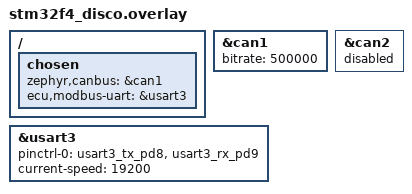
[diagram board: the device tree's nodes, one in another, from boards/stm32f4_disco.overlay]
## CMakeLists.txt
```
# SPDX-License-Identifier: Apache-2.0

cmake_minimum_required(VERSION 3.20.0)

find_package(Zephyr REQUIRED HINTS $ENV{ZEPHYR_BASE})
project(sensor_ecu LANGUAGES C)

target_include_directories(app PRIVATE src)

target_sources(app PRIVATE
  src/main.c
  src/data_model.c
  src/sensors_sim.c
  src/crc.c
  src/can_codec.c
  src/can_app.c
  src/dtc.c
  src/uds.c
  src/uds_server.c
  src/modbus_map.c
  src/modbus_rtu.c
  src/modbus_server.c
)
```

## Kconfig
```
# SPDX-License-Identifier: Apache-2.0

mainmenu "Sensor ECU"

config ECU_MODBUS_MIN_FRAME_GAP_US
	int "Minimum Modbus RTU silent interval (us)"
	default 0
	help
	  Lower bound for the RTU end-of-frame silent interval. On real UARTs
	  t3.5 is computed from the baud rate. A pseudo terminal delivers
	  bytes in bursts with host scheduling jitter, so the native_sim
	  build raises the bound to avoid splitting frames.

source "Kconfig.zephyr"
```

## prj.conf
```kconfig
# Logging
CONFIG_LOG=y
CONFIG_LOG_MODE_DEFERRED=y

# CAN + ISO-TP
CONFIG_CAN=y
CONFIG_ISOTP=y
CONFIG_ISOTP_RX_BUF_COUNT=4
CONFIG_ISOTP_RX_SF_FF_BUF_COUNT=2

# Modbus server fed through the raw ADU interface (see modbus_rtu.h)
CONFIG_MODBUS=y
CONFIG_MODBUS_ROLE_SERVER=y
CONFIG_MODBUS_RAW_ADU=y
CONFIG_MODBUS_NUMOF_RAW_ADU=1

# UART interrupt API for the RTU framer
CONFIG_SERIAL=y
CONFIG_UART_INTERRUPT_DRIVEN=y
CONFIG_UART_USE_RUNTIME_CONFIGURE=y

CONFIG_MAIN_STACK_SIZE=2048
CONFIG_SYSTEM_WORKQUEUE_STACK_SIZE=2048
CONFIG_THREAD_NAME=y
```

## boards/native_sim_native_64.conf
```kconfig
# A PTY delivers bytes with host scheduling jitter; see Kconfig help.
CONFIG_ECU_MODBUS_MIN_FRAME_GAP_US=5000
```

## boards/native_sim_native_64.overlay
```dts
/*
 * native_sim: CAN goes to the host SocketCAN interface vcan0 (override at
 * run time with --can-if), Modbus RTU runs on a second pseudo terminal.
 *
 * SPDX-License-Identifier: Apache-2.0
 */

/ {
	chosen {
		zephyr,canbus = &can0;
		ecu,modbus-uart = &uart1;
	};
};

&can0 {
	status = "okay";
	host-interface = "vcan0";
};

&uart1 {
	status = "okay";
};
```

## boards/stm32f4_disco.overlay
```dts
/*
 * STM32F4 Discovery (also what Renode emulates): CAN1 (PD0/PD1) at
 * 500 kbit/s, Modbus RTU on USART3 (PD8/PD9), console stays on USART2.
 *
 * CAN1 rather than the board default CAN2: CAN1 owns the shared filter
 * banks, and for the CAN2 slave Renode's STMCAN model numbers the filter
 * match index across all 28 banks instead of from CAN2SB as silicon does,
 * so Zephyr would route every received frame to no callback.
 *
 * SPDX-License-Identifier: Apache-2.0
 */

/ {
	chosen {
		zephyr,canbus = &can1;
		ecu,modbus-uart = &usart3;
	};
};

&can1 {
	bitrate = <500000>;
};

&can2 {
	status = "disabled";
};

&usart3 {
	pinctrl-0 = <&usart3_tx_pd8 &usart3_rx_pd9>;
	pinctrl-names = "default";
	current-speed = <19200>;
	status = "okay";
};
```

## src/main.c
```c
/*
 * Virtual industrial and automotive sensor node.
 *
 * main() owns the sampling loop and the slow supervision checks; CAN, UDS
 * and Modbus run in their own threads and only meet in the data model.
 *
 * SPDX-License-Identifier: Apache-2.0
 */

#include <zephyr/kernel.h>
#include <zephyr/logging/log.h>

#include "data_model.h"
#include "dtc.h"
#include "ecu_config.h"
#include "ecu_tasks.h"
#include "modbus_map.h"
#include "sensors_sim.h"

LOG_MODULE_REGISTER(main, LOG_LEVEL_INF);

int main(void)
{
	LOG_INF("Sensor ECU %s starting (serial %s)", ECU_FW_VERSION, ECU_SERIAL_NUMBER);

	dm_init();
	dtc_init();
	sensors_sim_init(0xC0FFEE);

	bool can_ok = can_app_start() == 0;

	if (can_ok && uds_server_start() != 0) {
		LOG_ERR("UDS server failed to start");
	}
	if (modbus_server_start() != 0) {
		LOG_ERR("Modbus server failed to start");
	}

	dm_set_state(FW_STATE_RUN);
	LOG_INF("ECU running (CAN %s)", can_ok ? "up" : "DOWN");

	bool sensor_fault_logged = false;

	while (true) {
		struct dm_snapshot s;
		struct sensor_sample sample;

		dm_get(&s);
		sensors_sim_sample(k_uptime_get_32(), s.fault_injection, &sample);
		dm_update_sensors(sample.temperature_dC, sample.vibration_cmm_s,
				  sample.out_of_range);

		dtc_report(DTC_SENSOR_OUT_OF_RANGE, sample.out_of_range);
		dtc_report(DTC_MODBUS_MASTER_TIMEOUT, mb_link_timed_out(k_uptime_get()));

		if (sample.out_of_range != sensor_fault_logged) {
			sensor_fault_logged = sample.out_of_range;
			LOG_INF("Sensor %s", sensor_fault_logged ? "out of range" : "back in range");
		}

		k_sleep(K_MSEC(s.sample_period_ms));
	}

	return 0;
}
```

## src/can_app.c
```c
/*
 * CAN front end: periodic SENSOR_STATUS / HEARTBEAT transmission and
 * ECU_COMMAND reception with rolling counter and CRC checks.
 *
 * SPDX-License-Identifier: Apache-2.0
 */

#include <string.h>

#include <zephyr/device.h>
#include <zephyr/devicetree.h>
#include <zephyr/drivers/can.h>
#include <zephyr/kernel.h>
#include <zephyr/logging/log.h>

#include "can_codec.h"
#include "data_model.h"
#include "dtc.h"
#include "ecu_config.h"
#include "ecu_tasks.h"

LOG_MODULE_REGISTER(can_app, LOG_LEVEL_INF);

#define CAN_TX_STACK 1024
#define CAN_RX_STACK 1024
#define CAN_TX_PRIO  5
#define CAN_RX_PRIO  6

static const struct device *const can_dev = DEVICE_DT_GET(DT_CHOSEN(zephyr_canbus));

CAN_MSGQ_DEFINE(cmd_msgq, 8);

K_THREAD_STACK_DEFINE(can_tx_stack, CAN_TX_STACK);
K_THREAD_STACK_DEFINE(can_rx_stack, CAN_RX_STACK);
static struct k_thread can_tx_thread;
static struct k_thread can_rx_thread;

static int send_frame(uint32_t id, const uint8_t data[8])
{
	struct can_frame frame = {
		.id = id,
		.dlc = CAN_CODEC_DLC,
	};

	memcpy(frame.data, data, CAN_CODEC_DLC);
	return can_send(can_dev, &frame, K_MSEC(20), NULL, NULL);
}

static void can_tx_loop(void *p1, void *p2, void *p3)
{
	int64_t next = k_uptime_get();
	uint8_t counter = 0;
	uint32_t ticks = 0;

	while (true) {
		struct dm_snapshot s;
		uint8_t data[8];

		dm_get(&s);

		struct sensor_status_msg status = {
			.temperature_dC = s.temperature_dC,
			.vibration_cmm_s = s.vibration_cmm_s,
			.alarm_active = s.alarm_active,
			.sensor_fault = s.sensor_fault,
			.counter = counter,
		};

		can_codec_pack_sensor_status(&status, data);
		if (send_frame(CAN_ID_SENSOR_STATUS, data) != 0) {
			LOG_DBG("SENSOR_STATUS not sent");
		}
		counter = (counter + 1) & 0x0F;

		if (ticks % (HEARTBEAT_PERIOD_MS / SENSOR_STATUS_PERIOD_MS) == 0) {
			size_t active = dtc_count_by_mask(DTC_STATUS_TEST_FAILED);
			struct heartbeat_msg hb = {
				.uptime_s = s.uptime_s,
				.fw_state = active ? FW_STATE_DEGRADED : s.state,
				.active_dtcs = (uint8_t)active,
			};

			can_codec_pack_heartbeat(&hb, data);
			(void)send_frame(CAN_ID_HEARTBEAT, data);
		}
		ticks++;

		/* Absolute deadlines keep the period free of cumulative drift. */
		next += SENSOR_STATUS_PERIOD_MS;
		k_sleep(K_TIMEOUT_ABS_MS(next));
	}
}

static void apply_command(const struct ecu_command_msg *cmd)
{
	if (cmd->sample_period_ms != CMD_SAMPLE_PERIOD_KEEP &&
	    dm_set_sample_period(cmd->sample_period_ms) != 0) {
		LOG_WRN("ECU_COMMAND: sample period %u out of range", cmd->sample_period_ms);
	}
	if (cmd->alarm_threshold_dC != CMD_ALARM_THRESHOLD_KEEP &&
	    dm_set_alarm_threshold(cmd->alarm_threshold_dC) != 0) {
		LOG_WRN("ECU_COMMAND: threshold %d out of range", cmd->alarm_threshold_dC);
	}
	dm_set_fault_injection(cmd->fault_injection);
	if (cmd->alarm_reset) {
		dm_reset_alarm();
	}

	LOG_INF("ECU_COMMAND applied: period=%u threshold=%d fault=%d reset=%d",
		cmd->sample_period_ms, cmd->alarm_threshold_dC, cmd->fault_injection,
		cmd->alarm_reset);
}

static void can_rx_loop(void *p1, void *p2, void *p3)
{
	struct can_frame frame;
	int last_counter = -1;

	while (true) {
		struct ecu_command_msg cmd;

		k_msgq_get(&cmd_msgq, &frame, K_FOREVER);

		int err = can_codec_unpack_ecu_command(frame.data, frame.dlc, &cmd);

		if (err == -EBADMSG) {
			LOG_WRN("ECU_COMMAND rejected: CRC error");
			dtc_report(DTC_COMMAND_CRC_ERROR, true);
			continue;
		}
		if (err) {
			LOG_WRN("ECU_COMMAND rejected: DLC %u", frame.dlc);
			continue;
		}
		dtc_report(DTC_COMMAND_CRC_ERROR, false);

		/* A repeated counter means a stale or replayed frame. */
		if (cmd.counter == last_counter) {
			LOG_WRN("ECU_COMMAND rejected: repeated counter %u", cmd.counter);
			continue;
		}
		last_counter = cmd.counter;

		apply_command(&cmd);
	}
}

static void can_state_changed(const struct device *dev, enum can_state state,
			      struct can_bus_err_cnt err_cnt, void *user_data)
{
	static bool was_bus_off;

	if (state == CAN_STATE_BUS_OFF) {
		was_bus_off = true;
		dtc_report(DTC_CAN_BUS_OFF, true);
	} else if (was_bus_off && state == CAN_STATE_ERROR_ACTIVE) {
		/* Recovered: testFailed clears, confirmed stays for the tester. */
		was_bus_off = false;
		dtc_report(DTC_CAN_BUS_OFF, false);
	}
}

const struct device *can_app_device(void)
{
	return can_dev;
}

int can_app_start(void)
{
	const struct can_filter cmd_filter = {
		.id = CAN_ID_ECU_COMMAND,
		.mask = CAN_STD_ID_MASK,
		.flags = 0,
	};
	int err;

	if (!device_is_ready(can_dev)) {
		LOG_ERR("CAN device %s not ready", can_dev->name);
		return -ENODEV;
	}

	err = can_set_bitrate(can_dev, CAN_BITRATE);
	if (err && err != -ENOTSUP && err != -ENOSYS) {
		LOG_WRN("can_set_bitrate: %d", err);
	}

	can_set_state_change_callback(can_dev, can_state_changed, NULL);

	err = can_add_rx_filter_msgq(can_dev, &cmd_msgq, &cmd_filter);
	if (err < 0) {
		LOG_ERR("ECU_COMMAND filter: %d", err);
		return err;
	}

	err = can_start(can_dev);
	if (err && err != -EALREADY) {
		LOG_ERR("can_start: %d", err);
		return err;
	}

	k_thread_create(&can_tx_thread, can_tx_stack, K_THREAD_STACK_SIZEOF(can_tx_stack),
			can_tx_loop, NULL, NULL, NULL, CAN_TX_PRIO, 0, K_NO_WAIT);
	k_thread_name_set(&can_tx_thread, "can_tx");
	k_thread_create(&can_rx_thread, can_rx_stack, K_THREAD_STACK_SIZEOF(can_rx_stack),
			can_rx_loop, NULL, NULL, NULL, CAN_RX_PRIO, 0, K_NO_WAIT);
	k_thread_name_set(&can_rx_thread, "can_rx");

	LOG_INF("CAN up on %s, %u bit/s", can_dev->name, CAN_BITRATE);
	return 0;
}
```

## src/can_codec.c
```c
/*
 * SPDX-License-Identifier: Apache-2.0
 */

#include <errno.h>
#include <string.h>

#include "can_codec.h"
#include "crc.h"

#define CRC_BYTE     7
#define COUNTER_BYTE 6

static void put_le16(uint8_t *p, uint16_t v)
{
	p[0] = (uint8_t)v;
	p[1] = (uint8_t)(v >> 8);
}

static uint16_t get_le16(const uint8_t *p)
{
	return (uint16_t)(p[0] | (p[1] << 8));
}

static void seal(uint8_t data[8], uint8_t counter)
{
	data[COUNTER_BYTE] = counter & 0x0F;
	data[CRC_BYTE] = crc8_sae_j1850(data, CRC_BYTE);
}

static int check(const uint8_t *data, uint8_t dlc)
{
	if (dlc != CAN_CODEC_DLC) {
		return -EINVAL;
	}
	if (crc8_sae_j1850(data, CRC_BYTE) != data[CRC_BYTE]) {
		return -EBADMSG;
	}
	return 0;
}

void can_codec_pack_sensor_status(const struct sensor_status_msg *msg, uint8_t data[8])
{
	memset(data, 0, CAN_CODEC_DLC);
	put_le16(&data[0], (uint16_t)msg->temperature_dC);
	put_le16(&data[2], msg->vibration_cmm_s);
	data[4] = (msg->alarm_active ? 0x01 : 0) | (msg->sensor_fault ? 0x02 : 0);
	seal(data, msg->counter);
}

int can_codec_unpack_sensor_status(const uint8_t *data, uint8_t dlc, struct sensor_status_msg *msg)
{
	int err = check(data, dlc);

	if (err) {
		return err;
	}
	msg->temperature_dC = (int16_t)get_le16(&data[0]);
	msg->vibration_cmm_s = get_le16(&data[2]);
	msg->alarm_active = data[4] & 0x01;
	msg->sensor_fault = data[4] & 0x02;
	msg->counter = data[COUNTER_BYTE] & 0x0F;
	return 0;
}

/* HEARTBEAT is not safety relevant, so it carries no counter or CRC. */
void can_codec_pack_heartbeat(const struct heartbeat_msg *msg, uint8_t data[8])
{
	memset(data, 0, CAN_CODEC_DLC);
	put_le16(&data[0], (uint16_t)msg->uptime_s);
	put_le16(&data[2], (uint16_t)(msg->uptime_s >> 16));
	data[4] = msg->fw_state;
	data[5] = msg->active_dtcs;
}

int can_codec_unpack_heartbeat(const uint8_t *data, uint8_t dlc, struct heartbeat_msg *msg)
{
	if (dlc != CAN_CODEC_DLC) {
		return -EINVAL;
	}
	msg->uptime_s = get_le16(&data[0]) | ((uint32_t)get_le16(&data[2]) << 16);
	msg->fw_state = data[4];
	msg->active_dtcs = data[5];
	return 0;
}

void can_codec_pack_ecu_command(const struct ecu_command_msg *msg, uint8_t data[8])
{
	memset(data, 0, CAN_CODEC_DLC);
	put_le16(&data[0], msg->sample_period_ms);
	put_le16(&data[2], (uint16_t)msg->alarm_threshold_dC);
	data[4] = (msg->fault_injection ? 0x01 : 0) | (msg->alarm_reset ? 0x02 : 0);
	seal(data, msg->counter);
}

int can_codec_unpack_ecu_command(const uint8_t *data, uint8_t dlc, struct ecu_command_msg *msg)
{
	int err = check(data, dlc);

	if (err) {
		return err;
	}
	msg->sample_period_ms = get_le16(&data[0]);
	msg->alarm_threshold_dC = (int16_t)get_le16(&data[2]);
	msg->fault_injection = data[4] & 0x01;
	msg->alarm_reset = data[4] & 0x02;
	msg->counter = data[COUNTER_BYTE] & 0x0F;
	return 0;
}
```

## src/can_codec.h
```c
/*
 * Pack and unpack the project CAN messages. The bit layout here must match
 * dbc/sensor_ecu.dbc; the integration tests decode live frames with cantools
 * to prove that it does.
 *
 * All multi-byte signals are little endian (Intel). Byte 6 carries a 4-bit
 * rolling counter and byte 7 a CRC-8 SAE J1850 over bytes 0..6.
 *
 * SPDX-License-Identifier: Apache-2.0
 */

#ifndef CAN_CODEC_H_
#define CAN_CODEC_H_

#include <stdbool.h>
#include <stdint.h>

#define CAN_CODEC_DLC 8

struct sensor_status_msg {
	int16_t temperature_dC;   /* 0.1 degC */
	uint16_t vibration_cmm_s; /* 0.01 mm/s */
	bool alarm_active;
	bool sensor_fault;
	uint8_t counter;          /* 0..15 */
};

struct heartbeat_msg {
	uint32_t uptime_s;
	uint8_t fw_state;
	uint8_t active_dtcs;
};

struct ecu_command_msg {
	uint16_t sample_period_ms; /* CMD_SAMPLE_PERIOD_KEEP = no change */
	int16_t alarm_threshold_dC; /* CMD_ALARM_THRESHOLD_KEEP = no change */
	bool fault_injection;
	bool alarm_reset;
	uint8_t counter;          /* 0..15 */
};

void can_codec_pack_sensor_status(const struct sensor_status_msg *msg, uint8_t data[8]);
int can_codec_unpack_sensor_status(const uint8_t *data, uint8_t dlc,
				   struct sensor_status_msg *msg);

void can_codec_pack_heartbeat(const struct heartbeat_msg *msg, uint8_t data[8]);
int can_codec_unpack_heartbeat(const uint8_t *data, uint8_t dlc, struct heartbeat_msg *msg);

void can_codec_pack_ecu_command(const struct ecu_command_msg *msg, uint8_t data[8]);
/* Returns 0, -EINVAL for a wrong DLC or -EBADMSG for a CRC mismatch. */
int can_codec_unpack_ecu_command(const uint8_t *data, uint8_t dlc, struct ecu_command_msg *msg);

#endif /* CAN_CODEC_H_ */
```

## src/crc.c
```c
/*
 * SPDX-License-Identifier: Apache-2.0
 */

#include "crc.h"

uint8_t crc8_sae_j1850(const uint8_t *data, size_t len)
{
	uint8_t crc = 0xFF;

	for (size_t i = 0; i < len; i++) {
		crc ^= data[i];
		for (int bit = 0; bit < 8; bit++) {
			crc = (crc & 0x80) ? (uint8_t)((crc << 1) ^ 0x1D) : (uint8_t)(crc << 1);
		}
	}

	return crc ^ 0xFF;
}

uint16_t crc16_modbus(const uint8_t *data, size_t len)
{
	uint16_t crc = 0xFFFF;

	for (size_t i = 0; i < len; i++) {
		crc ^= data[i];
		for (int bit = 0; bit < 8; bit++) {
			crc = (crc & 1) ? (crc >> 1) ^ 0xA001 : crc >> 1;
		}
	}
	return crc;
}
```

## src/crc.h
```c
/*
 * Checksums used on the two buses.
 *
 * SPDX-License-Identifier: Apache-2.0
 */

#ifndef CRC_H_
#define CRC_H_

#include <stddef.h>
#include <stdint.h>

/* CRC-8 SAE J1850 (poly 0x1D, init 0xFF, xorout 0xFF), as in AUTOSAR E2E. */
uint8_t crc8_sae_j1850(const uint8_t *data, size_t len);

/* Modbus RTU CRC-16 (poly 0xA001 reflected, init 0xFFFF). */
uint16_t crc16_modbus(const uint8_t *data, size_t len);

#endif /* CRC_H_ */
```

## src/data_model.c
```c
/*
 * SPDX-License-Identifier: Apache-2.0
 */

#include <errno.h>

#include <zephyr/kernel.h>

#include "data_model.h"
#include "ecu_config.h"

static K_MUTEX_DEFINE(dm_lock);

static struct {
	int16_t temperature_dC;
	uint16_t vibration_cmm_s;
	bool alarm_active;
	bool sensor_fault;
	bool fault_injection;
	uint16_t sample_period_ms;
	int16_t alarm_threshold_dC;
	enum fw_state state;
} dm;

/* Caller holds dm_lock. The alarm latches: crossing the threshold sets it,
 * only dm_reset_alarm() clears it.
 */
static void evaluate_alarm(void)
{
	if (dm.temperature_dC > dm.alarm_threshold_dC) {
		dm.alarm_active = true;
	}
}

void dm_init(void)
{
	k_mutex_lock(&dm_lock, K_FOREVER);
	dm.temperature_dC = 0;
	dm.vibration_cmm_s = 0;
	dm.alarm_active = false;
	dm.sensor_fault = false;
	dm.fault_injection = false;
	dm.sample_period_ms = SAMPLE_PERIOD_DEFAULT_MS;
	dm.alarm_threshold_dC = ALARM_THRESHOLD_DEFAULT;
	dm.state = FW_STATE_INIT;
	k_mutex_unlock(&dm_lock);
}

void dm_get(struct dm_snapshot *out)
{
	k_mutex_lock(&dm_lock, K_FOREVER);
	out->temperature_dC = dm.temperature_dC;
	out->vibration_cmm_s = dm.vibration_cmm_s;
	out->alarm_active = dm.alarm_active;
	out->sensor_fault = dm.sensor_fault;
	out->fault_injection = dm.fault_injection;
	out->sample_period_ms = dm.sample_period_ms;
	out->alarm_threshold_dC = dm.alarm_threshold_dC;
	out->state = dm.state;
	k_mutex_unlock(&dm_lock);

	out->uptime_s = (uint32_t)(k_uptime_get() / 1000);
}

int dm_set_sample_period(uint16_t period_ms)
{
	if (period_ms < SAMPLE_PERIOD_MIN_MS || period_ms > SAMPLE_PERIOD_MAX_MS) {
		return -EINVAL;
	}
	k_mutex_lock(&dm_lock, K_FOREVER);
	dm.sample_period_ms = period_ms;
	k_mutex_unlock(&dm_lock);
	return 0;
}

int dm_set_alarm_threshold(int16_t threshold_dC)
{
	if (threshold_dC < ALARM_THRESHOLD_MIN || threshold_dC > ALARM_THRESHOLD_MAX) {
		return -EINVAL;
	}
	k_mutex_lock(&dm_lock, K_FOREVER);
	dm.alarm_threshold_dC = threshold_dC;
	evaluate_alarm();
	k_mutex_unlock(&dm_lock);
	return 0;
}

void dm_set_fault_injection(bool enable)
{
	k_mutex_lock(&dm_lock, K_FOREVER);
	dm.fault_injection = enable;
	k_mutex_unlock(&dm_lock);
}

void dm_set_state(enum fw_state state)
{
	k_mutex_lock(&dm_lock, K_FOREVER);
	dm.state = state;
	k_mutex_unlock(&dm_lock);
}

void dm_update_sensors(int16_t temperature_dC, uint16_t vibration_cmm_s, bool sensor_fault)
{
	k_mutex_lock(&dm_lock, K_FOREVER);
	dm.temperature_dC = temperature_dC;
	dm.vibration_cmm_s = vibration_cmm_s;
	dm.sensor_fault = sensor_fault;
	evaluate_alarm();
	k_mutex_unlock(&dm_lock);
}

void dm_reset_alarm(void)
{
	k_mutex_lock(&dm_lock, K_FOREVER);
	dm.alarm_active = false;
	evaluate_alarm();
	k_mutex_unlock(&dm_lock);
}
```

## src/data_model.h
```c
/*
 * Shared sensor state. CAN, UDS and Modbus are all front ends onto this one
 * model; every access goes through a mutex so a threshold written over
 * Modbus is seen atomically by the CAN transmitter and vice versa.
 *
 * SPDX-License-Identifier: Apache-2.0
 */

#ifndef DATA_MODEL_H_
#define DATA_MODEL_H_

#include <stdbool.h>
#include <stdint.h>

enum fw_state {
	FW_STATE_INIT = 0,
	FW_STATE_RUN = 1,
	FW_STATE_DEGRADED = 2,
};

struct dm_snapshot {
	int16_t temperature_dC;
	uint16_t vibration_cmm_s;
	bool alarm_active;
	bool sensor_fault;
	bool fault_injection;
	uint16_t sample_period_ms;
	int16_t alarm_threshold_dC;
	uint32_t uptime_s;
	enum fw_state state;
};

void dm_init(void);

/* Consistent copy of the whole model, taken under the lock. */
void dm_get(struct dm_snapshot *out);

/* Setters validate ranges and return -EINVAL without changing anything. */
int dm_set_sample_period(uint16_t period_ms);
int dm_set_alarm_threshold(int16_t threshold_dC);
void dm_set_fault_injection(bool enable);
void dm_set_state(enum fw_state state);

/* New sensor values; re-evaluates the latched alarm. */
void dm_update_sensors(int16_t temperature_dC, uint16_t vibration_cmm_s, bool sensor_fault);

/*
 * Clear the latched alarm. The alarm only clears if the temperature is back
 * at or below the threshold, otherwise it stays active.
 */
void dm_reset_alarm(void);

#endif /* DATA_MODEL_H_ */
```

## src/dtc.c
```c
/*
 * SPDX-License-Identifier: Apache-2.0
 */

#include <zephyr/kernel.h>

#include "dtc.h"

/*
 * DTC numbers follow the SAE J2012 3-byte layout (2-byte code + failure
 * type byte). The U-codes reuse real network fault numbers; P0A10 is a
 * project-defined powertrain sensor code.
 */
static const uint32_t dtc_codes[DTC_COUNT] = {
	[DTC_SENSOR_OUT_OF_RANGE] = 0x0A1011,   /* P0A10-11 temperature out of range */
	[DTC_CAN_BUS_OFF] = 0xC07388,           /* U0073-88 CAN bus off */
	[DTC_MODBUS_MASTER_TIMEOUT] = 0xC10087, /* U0100-87 Modbus master missing */
	[DTC_COMMAND_CRC_ERROR] = 0xC41481,     /* U0414-81 invalid command CRC */
};

static uint8_t dtc_state[DTC_COUNT];
static struct k_spinlock dtc_lock;

void dtc_init(void)
{
	dtc_clear_all();
}

void dtc_report(enum dtc_id id, bool failed)
{
	if (id >= DTC_COUNT) {
		return;
	}

	K_SPINLOCK(&dtc_lock) {
		if (failed) {
			dtc_state[id] |= DTC_STATUS_TEST_FAILED | DTC_STATUS_TEST_FAILED_THIS_CYCLE |
					 DTC_STATUS_PENDING | DTC_STATUS_CONFIRMED;
		} else {
			dtc_state[id] &= ~DTC_STATUS_TEST_FAILED;
		}
	}
}

void dtc_clear_all(void)
{
	K_SPINLOCK(&dtc_lock) {
		for (int i = 0; i < DTC_COUNT; i++) {
			dtc_state[i] = 0;
		}
	}
}

uint32_t dtc_code(enum dtc_id id)
{
	return id < DTC_COUNT ? dtc_codes[id] : 0;
}

uint8_t dtc_status(enum dtc_id id)
{
	uint8_t status = 0;

	if (id < DTC_COUNT) {
		K_SPINLOCK(&dtc_lock) {
			status = dtc_state[id];
		}
	}
	return status;
}

size_t dtc_count_by_mask(uint8_t mask)
{
	return dtc_get_by_mask(mask, NULL, DTC_COUNT);
}

size_t dtc_get_by_mask(uint8_t mask, struct dtc_record *out, size_t max)
{
	size_t n = 0;

	K_SPINLOCK(&dtc_lock) {
		for (int i = 0; i < DTC_COUNT && n < max; i++) {
			if ((dtc_state[i] & mask) == 0) {
				continue;
			}
			if (out != NULL) {
				out[n].code = dtc_codes[i];
				out[n].status = dtc_state[i];
			}
			n++;
		}
	}
	return n;
}
```

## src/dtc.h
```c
/*
 * Diagnostic trouble code storage with ISO 14229 status bits. RAM only;
 * moving it to NVS/ZMS is the natural next step on real hardware.
 *
 * SPDX-License-Identifier: Apache-2.0
 */

#ifndef DTC_H_
#define DTC_H_

#include <stdbool.h>
#include <stddef.h>
#include <stdint.h>

enum dtc_id {
	DTC_SENSOR_OUT_OF_RANGE,
	DTC_CAN_BUS_OFF,
	DTC_MODBUS_MASTER_TIMEOUT,
	DTC_COMMAND_CRC_ERROR,
	DTC_COUNT,
};

/* ISO 14229-1 DTC status bits used by this ECU */
#define DTC_STATUS_TEST_FAILED            0x01
#define DTC_STATUS_TEST_FAILED_THIS_CYCLE 0x02
#define DTC_STATUS_PENDING                0x04
#define DTC_STATUS_CONFIRMED              0x08
#define DTC_STATUS_AVAILABILITY_MASK      0x0F

struct dtc_record {
	uint32_t code; /* 3-byte DTC number */
	uint8_t status;
};

void dtc_init(void);

/*
 * Report the result of a monitor. failed=true sets testFailed, pending and
 * confirmed. failed=false clears testFailed only, so a recovered fault
 * stays visible as confirmed until a tester clears it.
 */
void dtc_report(enum dtc_id id, bool failed);

void dtc_clear_all(void);

uint32_t dtc_code(enum dtc_id id);
uint8_t dtc_status(enum dtc_id id);

/* Number of DTCs whose status matches (status & mask) != 0. */
size_t dtc_count_by_mask(uint8_t mask);

/* Copy matching DTCs into out (up to max). Returns the number copied. */
size_t dtc_get_by_mask(uint8_t mask, struct dtc_record *out, size_t max);

#endif /* DTC_H_ */
```

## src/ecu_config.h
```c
/*
 * Project-wide constants for the sensor ECU.
 *
 * Every bus identifier, period and limit lives here so that the firmware,
 * the DBC file, the README tables and the host tools have one place to be
 * checked against.
 *
 * SPDX-License-Identifier: Apache-2.0
 */

#ifndef ECU_CONFIG_H_
#define ECU_CONFIG_H_

#define ECU_FW_VERSION    "1.0.0"
#define ECU_SERIAL_NUMBER "ZCM-ECU-000001"

/* CAN identifiers (11-bit, 500 kbit/s) */
#define CAN_ID_SENSOR_STATUS 0x100
#define CAN_ID_HEARTBEAT     0x101
#define CAN_ID_ECU_COMMAND   0x200
#define CAN_ID_UDS_REQUEST   0x7E0
#define CAN_ID_UDS_RESPONSE  0x7E8

#define CAN_BITRATE                500000
#define SENSOR_STATUS_PERIOD_MS    100
#define HEARTBEAT_PERIOD_MS        1000

/* ECU_COMMAND "leave unchanged" sentinels */
#define CMD_SAMPLE_PERIOD_KEEP   0U
#define CMD_ALARM_THRESHOLD_KEEP INT16_MAX

/* Modbus RTU server */
#define MODBUS_UNIT_ID            1
#define MODBUS_BAUDRATE           19200
#define MODBUS_MASTER_TIMEOUT_MS  5000

/* UDS */
#define UDS_S3_TIMEOUT_MS         5000
#define UDS_SECURITY_MAX_ATTEMPTS 3
#define UDS_SECURITY_LOCKOUT_MS   10000

/* Data model defaults and limits. Temperatures are in 0.1 degC. */
#define SAMPLE_PERIOD_DEFAULT_MS  100
#define SAMPLE_PERIOD_MIN_MS      10
#define SAMPLE_PERIOD_MAX_MS      10000
#define ALARM_THRESHOLD_DEFAULT   800
#define ALARM_THRESHOLD_MIN       -400
#define ALARM_THRESHOLD_MAX       1250
#define TEMP_VALID_MIN            -400
#define TEMP_VALID_MAX            1250

#endif /* ECU_CONFIG_H_ */
```

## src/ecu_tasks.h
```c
/*
 * Start functions for the bus front ends. Each returns 0 or a negative
 * errno; main() keeps the ECU running if one bus fails to come up.
 *
 * SPDX-License-Identifier: Apache-2.0
 */

#ifndef ECU_TASKS_H_
#define ECU_TASKS_H_

#include <zephyr/device.h>

int can_app_start(void);
const struct device *can_app_device(void);
int uds_server_start(void);
int modbus_server_start(void);

#endif /* ECU_TASKS_H_ */
```

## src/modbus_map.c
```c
/*
 * SPDX-License-Identifier: Apache-2.0
 */

#include <errno.h>

#include "data_model.h"
#include "dtc.h"
#include "ecu_config.h"
#include "modbus_map.h"

static bool link_seen;
static int64_t link_last_ms;

int mb_input_reg_rd(uint16_t addr, uint16_t *reg)
{
	struct dm_snapshot s;

	dm_get(&s);

	switch (addr) {
	case MB_IR_TEMPERATURE:
		*reg = (uint16_t)s.temperature_dC;
		return 0;
	case MB_IR_VIBRATION:
		*reg = s.vibration_cmm_s;
		return 0;
	case MB_IR_UPTIME_HI:
		*reg = (uint16_t)(s.uptime_s >> 16);
		return 0;
	case MB_IR_UPTIME_LO:
		*reg = (uint16_t)s.uptime_s;
		return 0;
	case MB_IR_ACTIVE_DTCS:
		*reg = (uint16_t)dtc_count_by_mask(DTC_STATUS_TEST_FAILED);
		return 0;
	default:
		return -ENOTSUP;
	}
}

int mb_discrete_input_rd(uint16_t addr, bool *state)
{
	struct dm_snapshot s;

	dm_get(&s);

	switch (addr) {
	case MB_DI_ALARM:
		*state = s.alarm_active;
		return 0;
	case MB_DI_SENSOR_FAULT:
		*state = s.sensor_fault;
		return 0;
	default:
		return -ENOTSUP;
	}
}

int mb_holding_reg_rd(uint16_t addr, uint16_t *reg)
{
	struct dm_snapshot s;

	dm_get(&s);

	switch (addr) {
	case MB_HR_SAMPLE_PERIOD:
		*reg = s.sample_period_ms;
		return 0;
	case MB_HR_ALARM_THRESHOLD:
		*reg = (uint16_t)s.alarm_threshold_dC;
		return 0;
	default:
		return -ENOTSUP;
	}
}

int mb_holding_reg_wr(uint16_t addr, uint16_t reg)
{
	switch (addr) {
	case MB_HR_SAMPLE_PERIOD:
		return dm_set_sample_period(reg);
	case MB_HR_ALARM_THRESHOLD:
		return dm_set_alarm_threshold((int16_t)reg);
	default:
		return -ENOTSUP;
	}
}

int mb_coil_rd(uint16_t addr, bool *state)
{
	struct dm_snapshot s;

	switch (addr) {
	case MB_COIL_ALARM_RESET:
		/* Momentary command, always reads back as off */
		*state = false;
		return 0;
	case MB_COIL_FAULT_INJECTION:
		dm_get(&s);
		*state = s.fault_injection;
		return 0;
	default:
		return -ENOTSUP;
	}
}

int mb_coil_wr(uint16_t addr, bool state)
{
	switch (addr) {
	case MB_COIL_ALARM_RESET:
		if (state) {
			dm_reset_alarm();
		}
		return 0;
	case MB_COIL_FAULT_INJECTION:
		dm_set_fault_injection(state);
		return 0;
	default:
		return -ENOTSUP;
	}
}

void mb_link_reset(void)
{
	link_seen = false;
	link_last_ms = 0;
}

void mb_link_activity(int64_t now_ms)
{
	link_seen = true;
	link_last_ms = now_ms;
}

bool mb_link_timed_out(int64_t now_ms)
{
	return link_seen && (now_ms - link_last_ms) > MODBUS_MASTER_TIMEOUT_MS;
}
```
